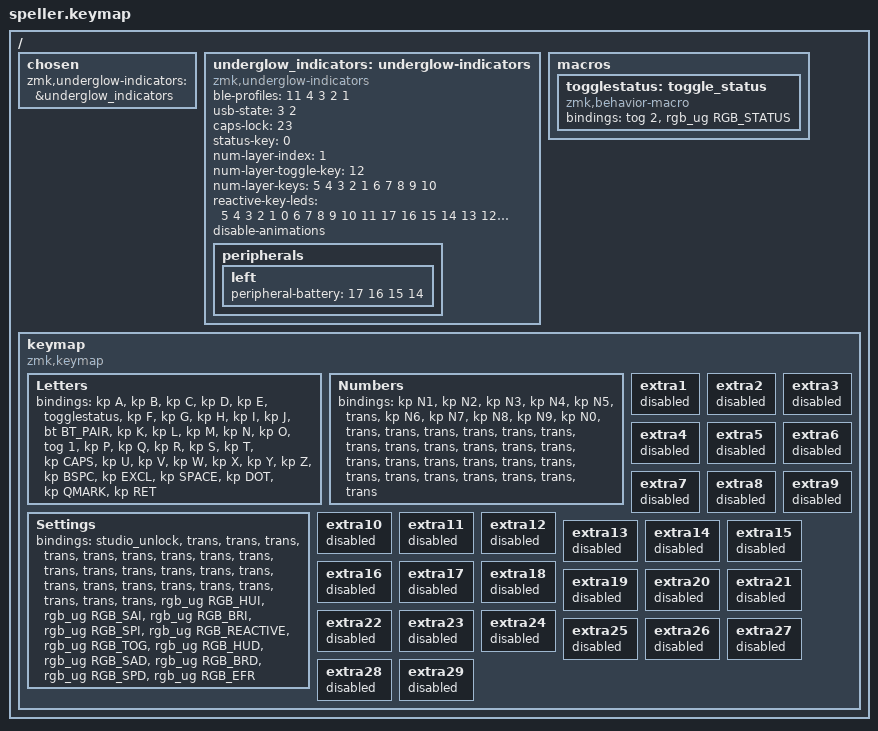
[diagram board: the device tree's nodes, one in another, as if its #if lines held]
#include <behaviors.dtsi>
#include <dt-bindings/zmk/keys.h>
#include <dt-bindings/zmk/rgb.h>
#include <dt-bindings/zmk/ext_power.h>
#include <dt-bindings/zmk/bt.h>

/ {
    chosen {
        zmk,underglow-indicators = &underglow_indicators;
    };

    /* LED Locations
        5   4   3   2   1   0
        6   7   8   9   10  11
        17  16  15  14  13  12
        18  19  20  21  22  23
        29  28  27  26  25  24
        30  31  32  33  34  35
    */

    underglow_indicators: underglow-indicators {
        compatible = "zmk,underglow-indicators";
        // First entry is the aggregate BLE status/pairing LED in consumer
        // mode — the BT (pair) key itself, so the hold-to-pair ramp and
        // pairing pulse appear on the key being held. In a non-consumer
        // build this is just profile 0's LED (on the BT key, off the top
        // row) — cosmetic only; release builds always enable consumer mode.
        ble-profiles = < 11 4 3 2 1 >;
        // USB status on the C and D keys — the USB port sits right between
        // them, so the white "typing goes over the cable" light is physically
        // anchored to the port
        usb-state = < 3 2 >;
        peripherals {
            left {
                peripheral-battery = < 17 16 15 14 >; // 25% 50% 75% 100% battery
            };
        };
        caps-lock = < 23 >; // Caps Lock LED
        status-key = < 0 >; // Amber pulse on the settings key (logo)
        num-layer-index = < 1 >; // Numbers layer
        num-layer-toggle-key = < 12 >; // tog 1 key (pulses)
        num-layer-keys = < 5 4 3 2 1 6 7 8 9 10 >; // N1-N0 keys (solid)

        // Reactive typing effect (toggled by RGB_REACTIVE, below). One LED per
        // keymap position: index N is the LED that flashes when position N is
        // pressed. This is the "LED Locations" grid above in keymap order
        // (positions 0..35, top-left to bottom-right) — the strip is wired in a
        // serpentine, so even rows run right-to-left.
        reactive-key-leds = <
             5  4  3  2  1  0
             6  7  8  9 10 11
            17 16 15 14 13 12
            18 19 20 21 22 23
            29 28 27 26 25 24
            30 31 32 33 34 35
        >;
        // Hide the breathe/spectrum/swirl animations: the effect cycle
        // (RGB_EFF/RGB_EFR) only lands on solid, so they can't be triggered by
        // accident. Solid + the reactive effect are the two Speller modes.
        disable-animations;
    };

macros {
    togglestatus: toggle_status {
      compatible = "zmk,behavior-macro";
      #binding-cells = <0>;
#ifdef RGB_STATUS
      bindings = <&tog 2>, <&rgb_ug RGB_STATUS>;
#else
      /* RGB_STATUS is a Cyboard ZMK extension (zmk-private@speller); against
       * upstream ZMK this is a plain toggled settings layer */
      bindings = <&tog 2>;
#endif
    };
  };

    keymap {
        compatible = "zmk,keymap";

        Letters {
            bindings = <
 &kp A      &kp B     &kp C     &kp D     &kp E     &togglestatus
#ifdef BT_PAIR
/* Consumer pairing (zmk-private@speller): the Bluetooth key is a first-class
 * base-layer key — tap selects the Bluetooth output, hold 3 s forgets all
 * devices and enters pairing mode (clear-all-and-pair). */
 &kp F      &kp G     &kp H     &kp I     &kp J     &bt BT_PAIR
#else
 &kp F      &kp G     &kp H     &kp I     &kp J     &studio_unlock
#endif
 &kp K      &kp L     &kp M     &kp N     &kp O     &tog 1
 &kp P      &kp Q     &kp R     &kp S     &kp T     &kp CAPS
 &kp U      &kp V     &kp W     &kp X     &kp Y     &kp Z
 &kp BSPC   &kp EXCL  &kp SPACE &kp DOT   &kp QMARK &kp RET
            >;
        };

        Numbers {
            bindings = <
 &kp N1  &kp N2  &kp N3  &kp N4  &kp N5  &trans
 &kp N6  &kp N7  &kp N8  &kp N9  &kp N0  &trans
 &trans  &trans  &trans  &trans  &trans  &trans
 &trans  &trans  &trans  &trans  &trans  &trans
 &trans  &trans  &trans  &trans  &trans  &trans
 &trans  &trans  &trans  &trans  &trans  &trans
            >;
        };

        Settings {
            bindings = <
#ifdef BT_PAIR
/* Consumer pairing mode: no profile keys needed — pairing lives on the
 * base-layer BT key (the &trans below it falls through, so hold-to-pair
 * works with the status display on too). The logo position falls through
 * to togglestatus so pressing the logo again exits; A unlocks ZMK Studio
 * (it sat on the logo key before the logo became the settings toggle). */
 &studio_unlock &trans      &trans       &trans       &trans        &trans
 &trans  &trans  &trans  &trans  &trans  &trans
#else
/* Upstream layout: the logo position must stay &trans so it falls through
 * to togglestatus — Settings is a toggle now, and anything else here
 * (e.g. BT_CLR) would soft-lock the layer. BT_CLR lives on the BT key
 * instead, shadowing base-layer &studio_unlock while Settings is on. */
 &bt BT_SEL 0  &bt BT_SEL 1 &bt BT_SEL 2 &bt BT_SEL 3 &bt BT_SEL 4  &trans
 &trans  &trans  &trans  &trans  &trans  &bt BT_CLR
#endif
 &trans  &trans  &trans  &trans  &trans  &trans
 &trans  &trans  &trans  &trans  &trans  &trans
/* Effect cycling (RGB_EFF/EFR) and speed (RGB_SPI/SPD) only affected the
 * now-hidden animations, so the top-right key toggles the reactive typing
 * mode instead (RGB_REACTIVE, a zmk-private@speller extension; against
 * upstream ZMK it falls back to a plain effect cycle). Pair it with the
 * backlight off (RGB_TOG) for the low-power "flash the key you press"
 * learning mode. */
#ifdef RGB_REACTIVE
 &trans  &rgb_ug RGB_HUI  &rgb_ug RGB_SAI  &rgb_ug RGB_BRI &rgb_ug RGB_SPI &rgb_ug RGB_REACTIVE
#else
 &trans  &rgb_ug RGB_HUI  &rgb_ug RGB_SAI  &rgb_ug RGB_BRI &rgb_ug RGB_SPI &rgb_ug RGB_EFF
#endif
 &rgb_ug RGB_TOG  &rgb_ug RGB_HUD  &rgb_ug RGB_SAD  &rgb_ug RGB_BRD &rgb_ug RGB_SPD &rgb_ug RGB_EFR
            >;
        };

        // The old Factory test layer is gone (2026-07-14): factory testing
        // now uses dedicated test firmware (zmk-environment/factory/), and
        // the layer was a soft-lock in customer hands — `&to` into a layer
        // of plain number keys had no way back until a power cycle.

        // Reserved empty layers: skipped in regular builds, but compiled into
        // ZMK Studio builds so users can add layers at runtime ("Add Layer"
        // only works for layers that exist in the firmware). ZMK tracks layer
        // state in a 32-bit mask, so 3 active + 29 reserved = 32 is the
        // maximum. Keep these AFTER all active layers: the initial layer
        // ordering assumes the active layers are the first keymap children.
        extra1 {
            status = "reserved";
        };

        extra2 {
            status = "reserved";
        };

        extra3 {
            status = "reserved";
        };

        extra4 {
            status = "reserved";
        };

        extra5 {
            status = "reserved";
        };

        extra6 {
            status = "reserved";
        };

        extra7 {
            status = "reserved";
        };

        extra8 {
            status = "reserved";
        };

        extra9 {
            status = "reserved";
        };

        extra10 {
            status = "reserved";
        };

        extra11 {
            status = "reserved";
        };

        extra12 {
            status = "reserved";
        };

        extra13 {
            status = "reserved";
        };

        extra14 {
            status = "reserved";
        };

        extra15 {
            status = "reserved";
        };

        extra16 {
            status = "reserved";
        };

        extra17 {
            status = "reserved";
        };

        extra18 {
            status = "reserved";
        };

        extra19 {
            status = "reserved";
        };

        extra20 {
            status = "reserved";
        };

        extra21 {
            status = "reserved";
        };

        extra22 {
            status = "reserved";
        };

        extra23 {
            status = "reserved";
        };

        extra24 {
            status = "reserved";
        };

        extra25 {
            status = "reserved";
        };

        extra26 {
            status = "reserved";
        };

        extra27 {
            status = "reserved";
        };

        extra28 {
            status = "reserved";
        };

        extra29 {
            status = "reserved";
        };
    };
};
